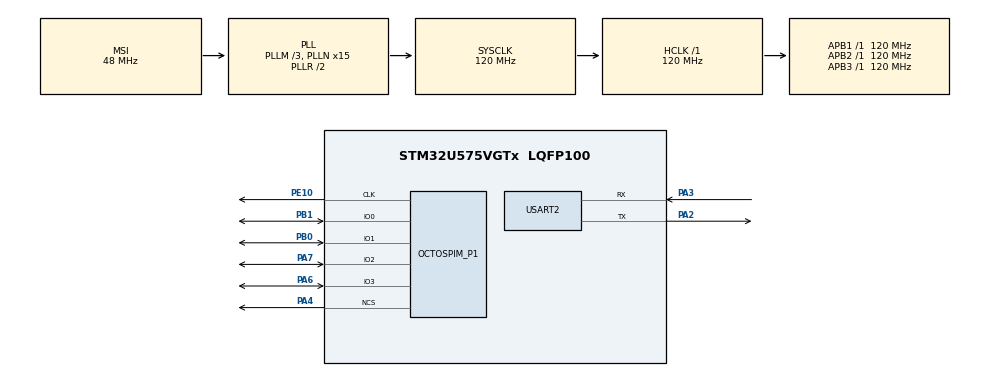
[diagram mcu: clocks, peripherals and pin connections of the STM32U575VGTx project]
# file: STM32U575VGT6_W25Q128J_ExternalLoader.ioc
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CORTEX_M33_NS.userName=CORTEX_M33
Mcu.Family=STM32U5
Mcu.Name=STM32U575VGTx
Mcu.Package=LQFP100
NVIC.ICACHE_IRQn=true\:0\:0\:false\:false\:true\:true\:true\:true
NVIC.PriorityGroup=NVIC_PRIORITYGROUP_4
OCTOSPI1.ClockPrescaler=2
OCTOSPI1.DeviceSize=24
PA2.Mode=Asynchronous
PA2.Signal=USART2_TX
PA3.Mode=Asynchronous
PA3.Signal=USART2_RX
PA4.GPIO_PuPd=GPIO_PULLUP
PA4.Mode=OCTOSPI1_Port1_NCS
PA4.Signal=OCTOSPIM_P1_NCS
PA6.Mode=OCTOSPI1_IOL_Port1L
PA6.Signal=OCTOSPIM_P1_IO3
PA7.Mode=OCTOSPI1_IOL_Port1L
PA7.Signal=OCTOSPIM_P1_IO2
PB0.Mode=OCTOSPI1_IOL_Port1L
PB0.Signal=OCTOSPIM_P1_IO1
PB1.Mode=OCTOSPI1_IOL_Port1L
PB1.Signal=OCTOSPIM_P1_IO0
PE10.Mode=O1_P1_CLK
PE10.Signal=OCTOSPIM_P1_CLK
ProjectManager.HeapSize=0x200
ProjectManager.StackSize=0x400
ProjectManager.TargetToolchain=STM32CubeIDE
RCC.ADCFreq_Value=16000000
RCC.AHBFreq_Value=120000000
RCC.APB1Freq_Value=120000000
RCC.APB1TimFreq_Value=120000000
RCC.APB2Freq_Value=120000000
RCC.APB2TimFreq_Value=120000000
RCC.APB3Freq_Value=120000000
RCC.CortexFreq_Value=120000000
RCC.EPOD_VALUE=48000000
RCC.HCLKFreq_Value=120000000
RCC.HSE_VALUE=16000000
RCC.HSI48_VALUE=48000000
RCC.HSI_VALUE=16000000
RCC.LSE_VALUE=32768
RCC.LSIDIV_VALUE=32000
RCC.MSIClockRange=RCC_MSIRANGE_0
RCC.MSI_VALUE=48000000
RCC.PLL2FRACN=0
RCC.PLL3FRACN=0
RCC.PLLFRACN=0
RCC.PLLM=3
RCC.PLLN=15
RCC.SYSCLKFreq_VALUE=120000000
RCC.SYSCLKSource=RCC_SYSCLKSOURCE_PLLCLK
RCC.USBFreq_Value=48000000
RCC.VCOOutputFreq_Value=240000000
USART2.VirtualMode-Asynchronous=VM_ASYNC
VP_ICACHE_VS_ENABLE_ICACHE_MEMORY.Mode=Memoryregions
VP_ICACHE_VS_ICACHE.Mode=DefaultMode
VP_LPBAMQUEUE_VS_QUEUE.Mode=QUEUEMODE
VP_LPBAM_VS_SIG1.Mode=SmartRun
VP_LPBAM_VS_SIG4.Mode=LPDMA1
VP_MEMORYMAP_VS_MEMORYMAP.Mode=CurAppReg
VP_OCTOSPI1_VS_quad.Mode=quad_mode
VP_PWR_VS_SECSignals.Mode=Security/Privilege
board=custom

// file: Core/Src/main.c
/* USER CODE BEGIN Header */
/**
  ******************************************************************************
  * @file           : main.c
  * @brief          : Main program body
  ******************************************************************************
  * @attention
  *
  * Copyright (c) 2025 STMicroelectronics.
  * All rights reserved.
  *
  * This software is licensed under terms that can be found in the LICENSE file
  * in the root directory of this software component.
  * If no LICENSE file comes with this software, it is provided AS-IS.
  *
  ******************************************************************************
  */
/* USER CODE END Header */
#include "main.h"
#include "icache.h"
#include "octospi.h"
#include "usart.h"
#include "gpio.h"

/* USER CODE BEGIN Includes */
#include "w25q128jvsq.h"
HAL_StatusTypeDef ret ;
extern OSPI_HandleTypeDef hospi1 ;

uint8_t txbuf[]= "Hello world";
uint8_t rxbuf[100];
uint8_t rxbuf2[100];

/* USER CODE END Includes */

void SystemClock_Config(void);

int main(void)
{

  /* MCU Configuration--------------------------------------------------------*/

  /* Reset of all peripherals, Initializes the Flash interface and the Systick. */
  HAL_Init();

  /* Configure the system clock */
  SystemClock_Config();

  /* Initialize all configured peripherals */
  MX_GPIO_Init();
  MX_OCTOSPI1_Init();
  MX_ICACHE_Init();
  MX_USART2_UART_Init();
  /* USER CODE BEGIN 2 */
  /*ret = W25Q128_OCTO_SPI_Init(&hospi1);

  if(ret!=HAL_OK){
	  while(1){};
  }

  // Erase the chip

  ret = W25Q128_OSPI_Erase_Chip(&hospi1);
  if(ret!=HAL_OK){
	  while(1){};
  }

  // Test the write and the read

  ret = W25Q128_OSPI_Read(&hospi1, &rxbuf, 0, 100);

  if(ret!=HAL_OK){
	  while(1){}
  }

  ret = W25Q128_OSPI_Write(&hospi1, &txbuf, 0, sizeof(txbuf));
  if(ret!=HAL_OK){
	  while(1){}
  }

  ret = W25Q128_OSPI_Read(&hospi1, &rxbuf2, 0, 100);

  if(ret!=HAL_OK){
	  while(1){}
  }

  ret = W25Q128_OSPI_EnableMemoryMappedMode(&hospi1);

  if(ret!=HAL_OK){
	  while(1){}
  }

*/
  /* USER CODE END 2 */

  /* Infinite loop */
  while (1)
  {

  }
}

void SystemClock_Config(void)
{
  RCC_OscInitTypeDef RCC_OscInitStruct = {0};
  RCC_ClkInitTypeDef RCC_ClkInitStruct = {0};

  /** Configure the main internal regulator output voltage
  */
  if (HAL_PWREx_ControlVoltageScaling(PWR_REGULATOR_VOLTAGE_SCALE1) != HAL_OK)
  {
    Error_Handler();
  }

  /** Initializes the CPU, AHB and APB buses clocks
  */
  RCC_OscInitStruct.OscillatorType = RCC_OSCILLATORTYPE_MSI;
  RCC_OscInitStruct.MSIState = RCC_MSI_ON;
  RCC_OscInitStruct.MSICalibrationValue = RCC_MSICALIBRATION_DEFAULT;
  RCC_OscInitStruct.MSIClockRange = RCC_MSIRANGE_0;
  RCC_OscInitStruct.PLL.PLLState = RCC_PLL_ON;
  RCC_OscInitStruct.PLL.PLLSource = RCC_PLLSOURCE_MSI;
  RCC_OscInitStruct.PLL.PLLMBOOST = RCC_PLLMBOOST_DIV4;
  RCC_OscInitStruct.PLL.PLLM = 3;
  RCC_OscInitStruct.PLL.PLLN = 15;
  RCC_OscInitStruct.PLL.PLLP = 2;
  RCC_OscInitStruct.PLL.PLLQ = 2;
  RCC_OscInitStruct.PLL.PLLR = 2;
  RCC_OscInitStruct.PLL.PLLRGE = RCC_PLLVCIRANGE_1;
  RCC_OscInitStruct.PLL.PLLFRACN = 0;
  if (HAL_RCC_OscConfig(&RCC_OscInitStruct) != HAL_OK)
  {
    Error_Handler();
  }

  /** Initializes the CPU, AHB and APB buses clocks
  */
  RCC_ClkInitStruct.ClockType = RCC_CLOCKTYPE_HCLK|RCC_CLOCKTYPE_SYSCLK
                              |RCC_CLOCKTYPE_PCLK1|RCC_CLOCKTYPE_PCLK2
                              |RCC_CLOCKTYPE_PCLK3;
  RCC_ClkInitStruct.SYSCLKSource = RCC_SYSCLKSOURCE_PLLCLK;
  RCC_ClkInitStruct.AHBCLKDivider = RCC_SYSCLK_DIV1;
  RCC_ClkInitStruct.APB1CLKDivider = RCC_HCLK_DIV1;
  RCC_ClkInitStruct.APB2CLKDivider = RCC_HCLK_DIV1;
  RCC_ClkInitStruct.APB3CLKDivider = RCC_HCLK_DIV1;

  if (HAL_RCC_ClockConfig(&RCC_ClkInitStruct, FLASH_LATENCY_3) != HAL_OK)
  {
    Error_Handler();
  }
}

void Error_Handler(void)
{
  __disable_irq();
  while (1)
  {
  }
}
